# C2000_FPU64_Registers register map
Vendor: Texas Instruments
Peripheral module from a debugger description file (folder C2000).
Address unit: 16 bits
Registers are 32-bit, access not given, no defined reset value unless marked. A register's access mark holds for its fields unless they carry their own. Offsets are as the file gives them; lines under a group give offsets from that group; [hi:lo] are bit positions; {n}, {i} and the like mark numbered series; 'fields as' and 'values as' point back to an identical list; <NAME> marks a mode.

## FPUREG — Floating-Point Unit Single Precision Registers
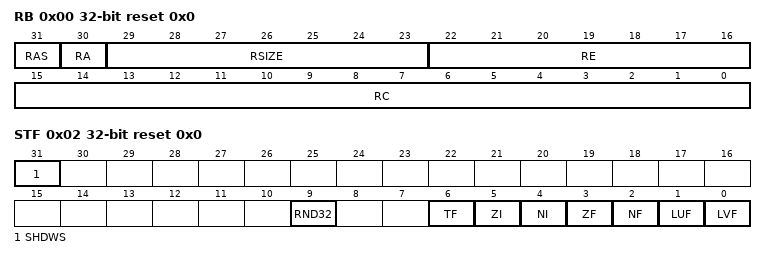
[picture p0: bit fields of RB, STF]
0x00 RB ro reset 0x0 — Repeat Block Register
  [31] RAS — Repeat block shadow active
  [30] RA — Repeat block active
  [29:23] RSIZE — Repeat block size
  [22:16] RE — Repeat block end
  [15:0] RC — Repeat count
0x02 STF rw reset 0x0 — Floating-Point Status Register
  [31] SHDWS — Shadow mode status
  [9] RND32 — Rounding mode
  [6] TF — Test flag
  [5] ZI — Zero integer flag
  [4] NI — Negative integer flag
  [3] ZF — Zero float flag
  [2] NF — Negative flaot flag
  [1] LUF — Latched underflow
  [0] LVF — Latched overflow
{0x10+4i} R{i}L (i=0..7)
{0x12+4i} R{i}H (i=0..7)
